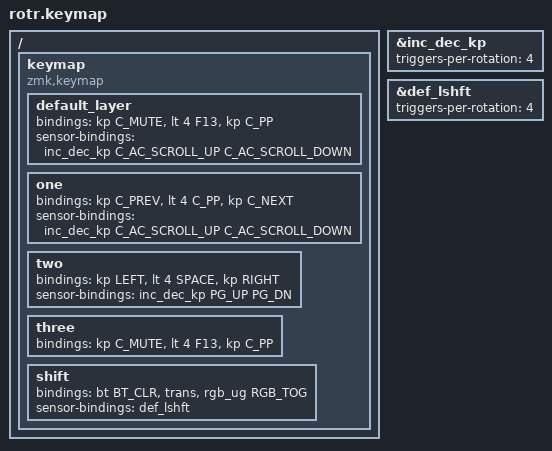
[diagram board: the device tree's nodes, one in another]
#include <behaviors.dtsi>
#include <dt-bindings/zmk/keys.h>
#include <dt-bindings/zmk/rgb.h>
#include <dt-bindings/zmk/bt.h>

&inc_dec_kp {
	triggers-per-rotation = <4>;
};
&def_lshft {
	triggers-per-rotation = <4>;
};

/ {
	keymap {
		compatible = "zmk,keymap";

		default_layer {
			//HOME | PLAY/PAUSE | END
			bindings = <&kp C_MUTE &lt 4 F13 &kp C_PP>;
			sensor-bindings = <&inc_dec_kp C_AC_SCROLL_UP C_AC_SCROLL_DOWN>;
		};
		one {
			//HOME | PLAY/PAUSE | END
			bindings = <&kp C_PREV &lt 4 C_PP &kp C_NEXT>;
			sensor-bindings = <&inc_dec_kp C_AC_SCROLL_UP C_AC_SCROLL_DOWN>;
		};
		two {
			//PREV | PLAY/PAUSE | NEXT
			bindings = <&kp LEFT &lt 4 SPACE &kp RIGHT>;
			sensor-bindings = <&inc_dec_kp PG_UP PG_DN>;
		};
		three {
			//PREV | PLAY/PAUSE | NEXT
			bindings = <&kp C_MUTE &lt 4 F13 &kp C_PP>;
		};
		shift {
			//PREV | PLAY/PAUSE | NEXT
			bindings = <&bt BT_CLR &trans &rgb_ug RGB_TOG>;
			sensor-bindings = <&def_lshft>;
		};
	};
};
